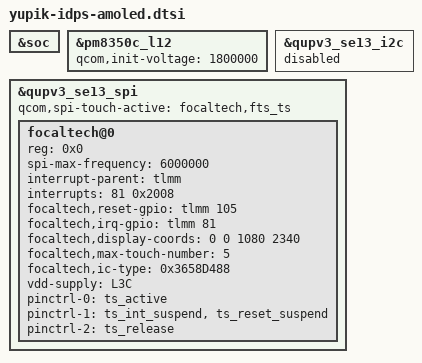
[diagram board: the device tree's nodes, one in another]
// SPDX-License-Identifier: BSD-3-Clause
/*
 * Copyright (c) 2025 Qualcomm Innovation Center, Inc. All rights reserved.
 */

#include "yupik-idp.dtsi"

&soc {
};

&pm8350c_l12 {
	qcom,init-voltage = <1800000>;
};

&qupv3_se13_i2c {
	status = "disabled";
};

&qupv3_se13_spi {
	status = "ok";
	qcom,spi-touch-active = "focaltech,fts_ts";

	focaltech@0 {
		reg = <0x0>;
		spi-max-frequency = <6000000>;
		interrupt-parent = <&tlmm>;
		interrupts = <81 0x2008>;
		focaltech,reset-gpio = <&tlmm 105 0x00>;
		focaltech,irq-gpio = <&tlmm 81 0x2008>;
		focaltech,display-coords = <0 0 1080 2340>;
		focaltech,max-touch-number = <5>;
		focaltech,ic-type = <0x3658D488>;

		vdd-supply = <&L3C>;

		pinctrl-names = "pmx_ts_active", "pmx_ts_suspend","pmx_ts_release";
		pinctrl-0 = <&ts_active>;
		pinctrl-1 = <&ts_int_suspend &ts_reset_suspend>;
		pinctrl-2 = <&ts_release>;

	};
};
